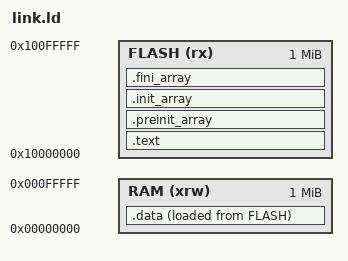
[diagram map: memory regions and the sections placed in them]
/* Entry Point */
ENTRY(main)

MEMORY
{
  RAM    (xrw)    : ORIGIN = 0x00000000,   LENGTH = 1024K
  FLASH    (rx)    : ORIGIN = 0x10000000,   LENGTH = 1024K
}

ENTRY(main)

/* Sections */
SECTIONS
{
  .text :
  {
    *(.text)           /* .text sections (code) */
    *(.text*)          /* .text* sections (code) */
  } >FLASH

  .preinit_array     :
  {
    . = ALIGN(4);
    PROVIDE_HIDDEN (__preinit_array_start = .);
    KEEP (*(.preinit_array*))
    PROVIDE_HIDDEN (__preinit_array_end = .);
    . = ALIGN(4);
  } >FLASH

  .init_array :
  {
    . = ALIGN(4);
    PROVIDE_HIDDEN (__init_array_start = .);
    KEEP (*(SORT(.init_array.*)))
    KEEP (*(.init_array*))
    PROVIDE_HIDDEN (__init_array_end = .);
    . = ALIGN(4);
  } >FLASH

  .fini_array :
  {
    . = ALIGN(4);
    PROVIDE_HIDDEN (__fini_array_start = .);
    KEEP (*(SORT(.fini_array.*)))
    KEEP (*(.fini_array*))
    PROVIDE_HIDDEN (__fini_array_end = .);
    . = ALIGN(4);
  } >FLASH

  /* Used by the startup to initialize data */
  _sidata = LOADADDR(.data);

  /* Initialized data sections into "RAM" Ram type memory */
  .data :
  {
    _sdata = .;        /* create a global symbol at data start */
    *(.nav_dev_tree)
    *(.data)           /* .data sections */
    *(.data*)          /* .data* sections */
  } >RAM AT> FLASH
}
